VERSION "37805-RAD-A820-M1 PCM TRANSMIT FRAMES"
NS_ :

BS_:
BU_: PCM NETWORK HDS INFERRED PROVEN

CM_ SG_ 166 THROTTLE_VLV "Throttle angle: native clamp(trunc(221C/80),0,255), with 0.005 deg/internal count. Raw 255 may be upper clipped.";
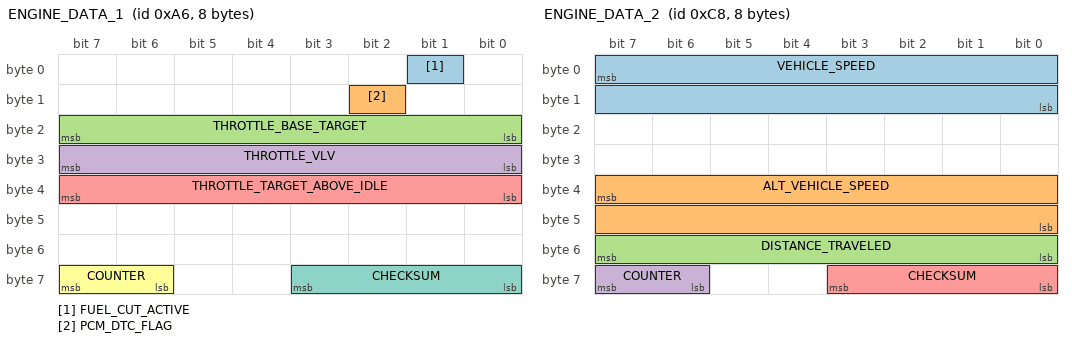
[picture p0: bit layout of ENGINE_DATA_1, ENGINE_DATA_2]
BO_ 166 ENGINE_DATA_1: 8 PCM
 SG_ FUEL_CUT_ACTIVE : 1|1@0+ (1,0) [0|1] "bool" PROVEN
 SG_ PCM_DTC_FLAG : 10|1@1+ (1,0) [0|1] "bool" PROVEN
 SG_ THROTTLE_BASE_TARGET : 23|8@0+ (0.4,0) [0|102] "deg" PROVEN
 SG_ THROTTLE_VLV : 31|8@0+ (0.4,0) [0|102] "deg" HDS
 SG_ THROTTLE_TARGET_ABOVE_IDLE : 39|8@0+ (0.4,0) [0|102] "deg" PROVEN
 SG_ COUNTER : 62|2@1+ (1,0) [0|3] "count" PROVEN
 SG_ CHECKSUM : 56|4@1+ (1,0) [0|15] "raw" PROVEN

CM_ SG_ 166 THROTTLE_BASE_TARGET "pedal/cruise target before rate limits and clamps";
CM_ SG_ 166 THROTTLE_TARGET_ABOVE_IDLE "THROTTLE_BASE_TARGET minus Idle Target TH";

CM_ SG_ 200 DISTANCE_TRAVELED "Modulo 2560 nominal metres; raw rolls over from 255 to 0.";
BO_ 200 ENGINE_DATA_2: 8 PCM
 SG_ VEHICLE_SPEED : 7|16@0+ (0.01,0) [0|255.99] "km/h" HDS
 SG_ ALT_VEHICLE_SPEED : 39|16@0+ (0.01,0) [0|255.99] "km/h" PROVEN
 SG_ DISTANCE_TRAVELED : 55|8@0+ (10,0) [0|2550] "m" PROVEN
 SG_ COUNTER : 62|2@1+ (1,0) [0|3] "count" PROVEN
 SG_ CHECKSUM : 56|4@1+ (1,0) [0|15] "raw" PROVEN

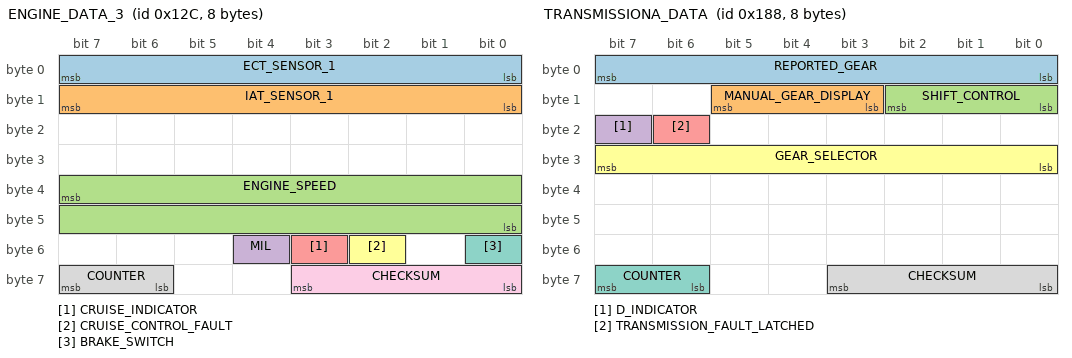
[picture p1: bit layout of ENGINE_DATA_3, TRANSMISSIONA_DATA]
BO_ 300 ENGINE_DATA_3: 8 PCM
 SG_ ECT_SENSOR_1 : 7|8@0+ (1,-40) [-40|150] "degC" HDS
 SG_ IAT_SENSOR_1 : 15|8@0+ (1,-40) [-40|150] "degC" HDS
 SG_ ENGINE_SPEED : 39|16@0+ (1,0) [0|32767] "rpm" HDS
 SG_ MIL : 52|1@1+ (1,0) [0|1] "bool" HDS
 SG_ CRUISE_INDICATOR : 51|1@1+ (1,0) [0|1] "bool" HDS
 SG_ CRUISE_CONTROL_FAULT : 50|1@1+ (1,0) [0|1] "bool" PROVEN
 SG_ BRAKE_SWITCH : 48|1@1+ (1,0) [0|1] "bool" HDS
 SG_ COUNTER : 62|2@1+ (1,0) [0|3] "count" PROVEN
 SG_ CHECKSUM : 56|4@1+ (1,0) [0|15] "raw" PROVEN

VAL_ 300 ECT_SENSOR_1 255 "Invalid" ;
VAL_ 300 IAT_SENSOR_1 255 "Invalid" ;
CM_ SG_ 300 MIL "Check-engine lamp";
CM_ SG_ 300 CRUISE_CONTROL_FAULT "Throttle failsafe mode or latched cruise set-speed consistency fault, copied during qualified cruise updates; may retain its previous value outside those updates.";

BO_ 392 TRANSMISSIONA_DATA: 8 PCM
 SG_ REPORTED_GEAR : 7|8@0+ (1,0) [0|255] "code" PROVEN
 SG_ MANUAL_GEAR_DISPLAY : 11|3@1+ (1,0) [0|7] "code" PROVEN
 SG_ SHIFT_CONTROL : 8|3@1+ (1,0) [0|7] "code" HDS
 SG_ D_INDICATOR : 23|1@1+ (1,0) [0|1] "bool" HDS
 SG_ TRANSMISSION_FAULT_LATCHED : 22|1@1+ (1,0) [0|1] "bool" PROVEN
 SG_ GEAR_SELECTOR : 31|8@0+ (1,0) [0|255] "code" PROVEN
 SG_ COUNTER : 62|2@1+ (1,0) [0|3] "count" PROVEN
 SG_ CHECKSUM : 56|4@1+ (1,0) [0|15] "raw" PROVEN

VAL_ 392 REPORTED_GEAR 0 "Unavailable" 1 "1" 2 "2" 3 "3" 4 "4" 5 "5" 6 "Reverse" 7 "Transition" ;
VAL_ 392 MANUAL_GEAR_DISPLAY 0 "Inactive" 1 "1" 2 "2" 3 "3" 4 "4" 5 "5" 7 "Unavailable" ;
VAL_ 392 SHIFT_CONTROL 0 "P/N" 1 "1st" 2 "2nd" 3 "3rd" 4 "4th" 5 "5th" 6 "R" ;
VAL_ 392 GEAR_SELECTOR 0 "BetweenOrInvalid" 1 "P" 2 "R" 4 "N" 8 "D" 32 "D3" 64 "2" 128 "1" ;

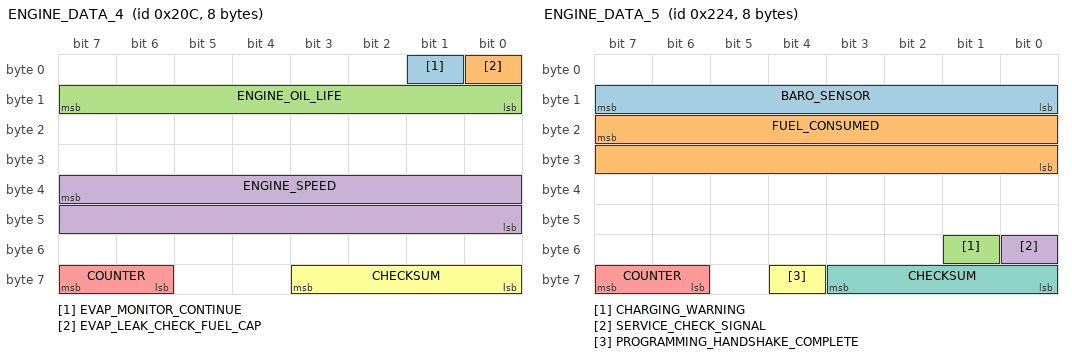
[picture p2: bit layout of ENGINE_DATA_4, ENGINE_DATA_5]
BO_ 524 ENGINE_DATA_4: 8 PCM
 SG_ EVAP_MONITOR_CONTINUE : 1|1@1+ (1,0) [0|1] "bool" PROVEN
 SG_ EVAP_LEAK_CHECK_FUEL_CAP : 0|1@1+ (1,0) [0|1] "bool" PROVEN
 SG_ ENGINE_OIL_LIFE : 15|8@0+ (1,0) [0|127] "%" HDS
 SG_ ENGINE_SPEED : 39|16@0+ (1,0) [0|32767] "rpm" HDS
 SG_ COUNTER : 62|2@1+ (1,0) [0|3] "count" PROVEN
 SG_ CHECKSUM : 56|4@1+ (1,0) [0|15] "raw" PROVEN

CM_ SG_ 548 BARO_SENSOR "Mid-bin kPa estimate from the native pressure encoder; raw 0 lower clipped, raw 255 fault or upper saturation.";
CM_ SG_ 548 FUEL_CONSUMED "Working mL estimate from transferred calibration; not independently metered for this firmware. Raw counter wraps modulo 65536; compare modulo deltas.";
BO_ 548 ENGINE_DATA_5: 8 PCM
 SG_ BARO_SENSOR : 15|8@0+ (0.357105,12.3347525) [12.691857500000001|103.0394225] "kPa" HDS
 SG_ FUEL_CONSUMED : 23|16@0+ (0.105585,0) [0|6919.512975] "mL" INFERRED
 SG_ CHARGING_WARNING : 49|1@1+ (1,0) [0|1] "bool" PROVEN
 SG_ SERVICE_CHECK_SIGNAL : 48|1@1+ (1,0) [0|1] "bool" HDS
 SG_ COUNTER : 62|2@1+ (1,0) [0|3] "count" PROVEN
 SG_ PROGRAMMING_HANDSHAKE_COMPLETE : 60|1@1+ (1,0) [0|1] "bool" PROVEN
 SG_ CHECKSUM : 56|4@1+ (1,0) [0|15] "raw" PROVEN

VAL_ 548 SERVICE_CHECK_SIGNAL 0 "OPEN" 1 "SHORT" ;
VAL_ 548 BARO_SENSOR 0 "Lower_clipped" 255 "Fault_or_saturated" ;
CM_ SG_ 548 PROGRAMMING_HANDSHAKE_COMPLETE "PGMFI diagnostic handshake";
